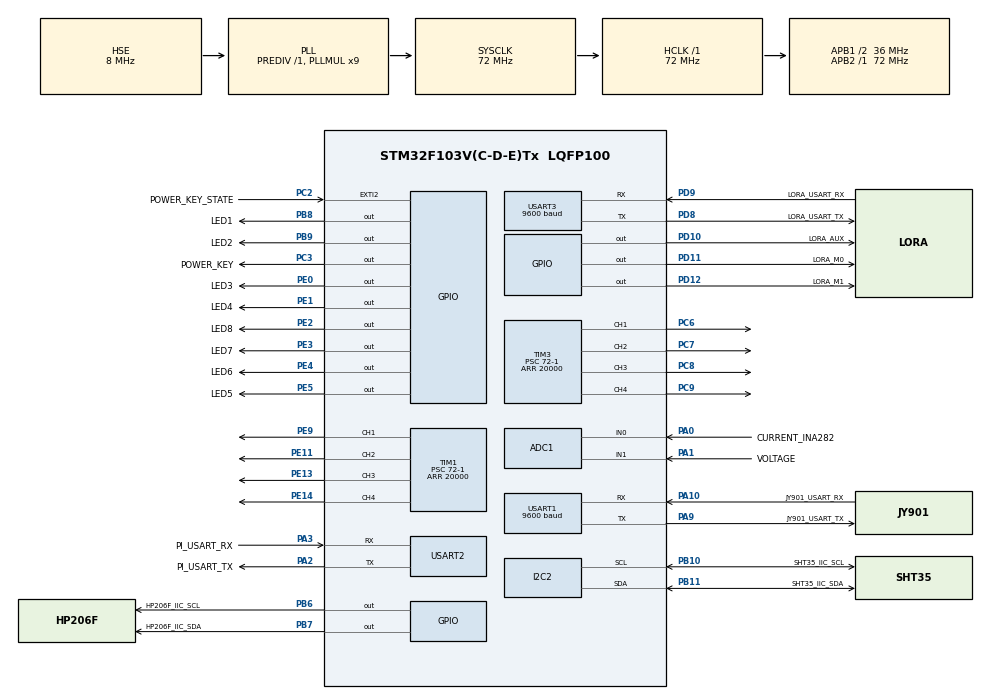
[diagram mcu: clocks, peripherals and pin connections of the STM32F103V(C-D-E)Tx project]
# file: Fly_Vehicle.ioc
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ADC1.Channel-0\#ChannelRegularConversion=ADC_CHANNEL_0
ADC1.Channel-3\#ChannelRegularConversion=ADC_CHANNEL_1
ADC1.ContinuousConvMode=ENABLE
ADC1.InjNumberOfConversion=0
ADC1.NbrOfConversion=2
ADC1.NbrOfConversionFlag=1
ADC1.Rank-0\#ChannelRegularConversion=1
ADC1.Rank-3\#ChannelRegularConversion=2
ADC1.SamplingTime-0\#ChannelRegularConversion=ADC_SAMPLETIME_239CYCLES_5
ADC1.SamplingTime-3\#ChannelRegularConversion=ADC_SAMPLETIME_239CYCLES_5
ADC1.master=1
Dma.ADC1.2.Direction=DMA_PERIPH_TO_MEMORY
Dma.ADC1.2.Instance=DMA1_Channel1
Dma.ADC1.2.MemDataAlignment=DMA_MDATAALIGN_WORD
Dma.ADC1.2.MemInc=DMA_MINC_ENABLE
Dma.ADC1.2.Mode=DMA_CIRCULAR
Dma.ADC1.2.PeriphDataAlignment=DMA_PDATAALIGN_WORD
Dma.ADC1.2.PeriphInc=DMA_PINC_DISABLE
Dma.ADC1.2.Priority=DMA_PRIORITY_LOW
Dma.Request0=USART1_RX
Dma.Request1=USART3_RX
Dma.Request2=ADC1
Dma.Request3=USART2_RX
Dma.Request4=USART2_TX
Dma.USART1_RX.0.Direction=DMA_PERIPH_TO_MEMORY
Dma.USART1_RX.0.Instance=DMA1_Channel5
Dma.USART1_RX.0.MemDataAlignment=DMA_MDATAALIGN_BYTE
Dma.USART1_RX.0.MemInc=DMA_MINC_ENABLE
Dma.USART1_RX.0.Mode=DMA_CIRCULAR
Dma.USART1_RX.0.PeriphDataAlignment=DMA_PDATAALIGN_BYTE
Dma.USART1_RX.0.PeriphInc=DMA_PINC_DISABLE
Dma.USART1_RX.0.Priority=DMA_PRIORITY_LOW
Dma.USART2_RX.3.Direction=DMA_PERIPH_TO_MEMORY
Dma.USART2_RX.3.Instance=DMA1_Channel6
Dma.USART2_RX.3.MemDataAlignment=DMA_MDATAALIGN_BYTE
Dma.USART2_RX.3.MemInc=DMA_MINC_ENABLE
Dma.USART2_RX.3.Mode=DMA_CIRCULAR
Dma.USART2_RX.3.PeriphDataAlignment=DMA_PDATAALIGN_BYTE
Dma.USART2_RX.3.PeriphInc=DMA_PINC_DISABLE
Dma.USART2_RX.3.Priority=DMA_PRIORITY_LOW
Dma.USART2_TX.4.Direction=DMA_MEMORY_TO_PERIPH
Dma.USART2_TX.4.Instance=DMA1_Channel7
Dma.USART2_TX.4.MemDataAlignment=DMA_MDATAALIGN_BYTE
Dma.USART2_TX.4.MemInc=DMA_MINC_ENABLE
Dma.USART2_TX.4.Mode=DMA_NORMAL
Dma.USART2_TX.4.PeriphDataAlignment=DMA_PDATAALIGN_BYTE
Dma.USART2_TX.4.PeriphInc=DMA_PINC_DISABLE
Dma.USART2_TX.4.Priority=DMA_PRIORITY_LOW
Dma.USART3_RX.1.Direction=DMA_PERIPH_TO_MEMORY
Dma.USART3_RX.1.Instance=DMA1_Channel3
Dma.USART3_RX.1.MemDataAlignment=DMA_MDATAALIGN_BYTE
Dma.USART3_RX.1.MemInc=DMA_MINC_ENABLE
Dma.USART3_RX.1.Mode=DMA_CIRCULAR
Dma.USART3_RX.1.PeriphDataAlignment=DMA_PDATAALIGN_BYTE
Dma.USART3_RX.1.PeriphInc=DMA_PINC_DISABLE
Dma.USART3_RX.1.Priority=DMA_PRIORITY_LOW
FREERTOS.INCLUDE_vTaskDelayUntil=1
FREERTOS.Tasks01=messageTask,0,500,message_Task_Function,As weak,NULL,Dynamic,NULL,NULL;sensorTask,-3,128,sensor_Task_Function,As weak,NULL,Dynamic,NULL,NULL;controlTask,-3,128,control_Task_Function,As weak,NULL,Dynamic,NULL,NULL;imuTask,-3,128,imu_Task_Function,As weak,NULL,Dynamic,NULL,NULL;ledTask,-3,128,led_Task_Function,As weak,NULL,Dynamic,NULL,NULL;pressureTask,2,128,pressure_Task_Function,As weak,NULL,Dynamic,NULL,NULL
FREERTOS.configTOTAL_HEAP_SIZE=8192
Mcu.Family=STM32F1
Mcu.Name=STM32F103V(C-D-E)Tx
Mcu.Package=LQFP100
NVIC.DMA1_Channel1_IRQn=true\:5\:0\:false\:false\:true\:true\:false\:true
NVIC.DMA1_Channel3_IRQn=true\:5\:0\:false\:false\:true\:true\:false\:true
NVIC.DMA1_Channel5_IRQn=true\:5\:0\:false\:false\:true\:true\:false\:true
NVIC.DMA1_Channel6_IRQn=true\:5\:0\:false\:false\:true\:true\:false\:true
NVIC.DMA1_Channel7_IRQn=true\:5\:0\:false\:false\:true\:true\:false\:true
NVIC.EXTI2_IRQn=true\:5\:0\:false\:false\:true\:true\:true\:true
NVIC.PriorityGroup=NVIC_PRIORITYGROUP_4
NVIC.TIM7_IRQn=true\:0\:0\:false\:false\:true\:false\:false\:true
NVIC.TimeBase=TIM7_IRQn
NVIC.TimeBaseIP=TIM7
NVIC.USART1_IRQn=true\:5\:0\:false\:false\:true\:true\:true\:true
NVIC.USART2_IRQn=true\:5\:0\:false\:false\:true\:true\:true\:true
NVIC.USART3_IRQn=true\:5\:0\:false\:false\:true\:true\:true\:true
OSC_IN.Mode=HSE-External-Oscillator
OSC_IN.Signal=RCC_OSC_IN
OSC_OUT.Mode=HSE-External-Oscillator
OSC_OUT.Signal=RCC_OSC_OUT
PA0-WKUP.GPIO_Label=CURRENT_INA282
PA0-WKUP.Signal=ADCx_IN0
PA1.GPIO_Label=VOLTAGE
PA1.Signal=ADCx_IN1
PA10.GPIO_Label=JY901_USART_RX
PA10.Mode=Asynchronous
PA10.Signal=USART1_RX
PA13.Mode=Serial_Wire
PA13.Signal=SYS_JTMS-SWDIO
PA14.Mode=Serial_Wire
PA14.Signal=SYS_JTCK-SWCLK
PA2.GPIO_Label=PI_USART_TX
PA2.Mode=Asynchronous
PA2.Signal=USART2_TX
PA3.GPIO_Label=PI_USART_RX
PA3.Mode=Asynchronous
PA3.Signal=USART2_RX
PA9.GPIO_Label=JY901_USART_TX
PA9.Mode=Asynchronous
PA9.Signal=USART1_TX
PB10.GPIO_Label=SHT35_IIC_SCL
PB10.Mode=I2C
PB10.Signal=I2C2_SCL
PB11.GPIO_Label=SHT35_IIC_SDA
PB11.Mode=I2C
PB11.Signal=I2C2_SDA
PB6.GPIO_Label=HP206F_IIC_SCL
PB6.GPIO_Speed=GPIO_SPEED_FREQ_HIGH
PB6.PinState=GPIO_PIN_SET
PB6.Signal=GPIO_Output
PB7.GPIO_Label=HP206F_IIC_SDA
PB7.GPIO_Speed=GPIO_SPEED_FREQ_HIGH
PB7.PinState=GPIO_PIN_SET
PB7.Signal=GPIO_Output
PB8.GPIO_Label=LED1
PB8.Signal=GPIO_Output
PB9.GPIO_Label=LED2
PB9.Signal=GPIO_Output
PC2.GPIO_Label=POWER_KEY_STATE
PC2.GPIO_ModeDefaultEXTI=GPIO_MODE_IT_FALLING
PC2.Signal=GPXTI2
PC3.GPIO_Label=POWER_KEY
PC3.PinState=GPIO_PIN_RESET
PC3.Signal=GPIO_Output
PC6.Signal=S_TIM3_CH1
PC7.Signal=S_TIM3_CH2
PC8.Signal=S_TIM3_CH3
PC9.Signal=S_TIM3_CH4
PD10.GPIO_Label=LORA_AUX
PD10.Signal=GPIO_Output
PD11.GPIO_Label=LORA_M0
PD11.Signal=GPIO_Output
PD12.GPIO_Label=LORA_M1
PD12.Signal=GPIO_Output
PD8.GPIO_Label=LORA_USART_TX
PD8.Mode=Asynchronous
PD8.Signal=USART3_TX
PD9.GPIO_Label=LORA_USART_RX
PD9.Mode=Asynchronous
PD9.Signal=USART3_RX
PE0.GPIO_Label=LED3
PE0.Signal=GPIO_Output
PE1.GPIO_Label=LED4
PE1.Signal=GPIO_Output
PE11.Signal=S_TIM1_CH2
PE13.Signal=S_TIM1_CH3
PE14.Signal=S_TIM1_CH4
PE2.GPIO_Label=LED8
PE2.Signal=GPIO_Output
PE3.GPIO_Label=LED7
PE3.Signal=GPIO_Output
PE4.GPIO_Label=LED6
PE4.Signal=GPIO_Output
PE5.GPIO_Label=LED5
PE5.Signal=GPIO_Output
PE9.Signal=S_TIM1_CH1
ProjectManager.HeapSize=0x200
ProjectManager.StackSize=0x400
ProjectManager.TargetToolchain=MDK-ARM V5
RCC.ADCPresc=RCC_ADCPCLK2_DIV6
RCC.AHBFreq_Value=72000000
RCC.APB1CLKDivider=RCC_HCLK_DIV2
RCC.APB1Freq_Value=36000000
RCC.APB1TimFreq_Value=72000000
RCC.APB2Freq_Value=72000000
RCC.APB2TimFreq_Value=72000000
RCC.HCLKFreq_Value=72000000
RCC.PLLMUL=RCC_PLL_MUL9
RCC.PLLSourceVirtual=RCC_PLLSOURCE_HSE
RCC.SYSCLKFreq_VALUE=72000000
RCC.SYSCLKSource=RCC_SYSCLKSOURCE_PLLCLK
RCC.USBFreq_Value=72000000
SH.ADCx_IN0.0=ADC1_IN0,IN0
SH.ADCx_IN1.0=ADC1_IN1,IN1
SH.S_TIM1_CH1.0=TIM1_CH1,PWM Generation1 CH1
SH.S_TIM1_CH2.0=TIM1_CH2,PWM Generation2 CH2
SH.S_TIM1_CH3.0=TIM1_CH3,PWM Generation3 CH3
SH.S_TIM1_CH4.0=TIM1_CH4,PWM Generation4 CH4
SH.S_TIM3_CH1.0=TIM3_CH1,PWM Generation1 CH1
SH.S_TIM3_CH2.0=TIM3_CH2,PWM Generation2 CH2
SH.S_TIM3_CH3.0=TIM3_CH3,PWM Generation3 CH3
SH.S_TIM3_CH4.0=TIM3_CH4,PWM Generation4 CH4
TIM1.Channel-PWM\ Generation1\ CH1=TIM_CHANNEL_1
TIM1.Channel-PWM\ Generation2\ CH2=TIM_CHANNEL_2
TIM1.Channel-PWM\ Generation3\ CH3=TIM_CHANNEL_3
TIM1.Channel-PWM\ Generation4\ CH4=TIM_CHANNEL_4
TIM1.Period=20000
TIM1.Prescaler=72-1
TIM1.Pulse-PWM\ Generation1\ CH1=1500
TIM1.Pulse-PWM\ Generation2\ CH2=1500
TIM1.Pulse-PWM\ Generation3\ CH3=1500
TIM1.Pulse-PWM\ Generation4\ CH4=1500
TIM3.Channel-PWM\ Generation1\ CH1=TIM_CHANNEL_1
TIM3.Channel-PWM\ Generation2\ CH2=TIM_CHANNEL_2
TIM3.Channel-PWM\ Generation3\ CH3=TIM_CHANNEL_3
TIM3.Channel-PWM\ Generation4\ CH4=TIM_CHANNEL_4
TIM3.Period=20000
TIM3.Prescaler=72-1
TIM3.Pulse-PWM\ Generation1\ CH1=1500
TIM3.Pulse-PWM\ Generation2\ CH2=1500
TIM3.Pulse-PWM\ Generation3\ CH3=1500
TIM3.Pulse-PWM\ Generation4\ CH4=1500
TIM6.Period=1
TIM6.Prescaler=72-1
USART1.BaudRate=9600
USART1.VirtualMode=VM_ASYNC
USART2.VirtualMode=VM_ASYNC
USART3.BaudRate=9600
USART3.VirtualMode=VM_ASYNC
VP_FREERTOS_VS_CMSIS_V1.Mode=CMSIS_V1
VP_SYS_VS_tim7.Mode=TIM7
VP_TIM6_VS_ClockSourceINT.Mode=Enable_Timer
board=custom

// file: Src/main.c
/* USER CODE BEGIN Header */
/**
  ******************************************************************************
  * @file           : main.c
  * @brief          : Main program body
  ******************************************************************************
  * @attention
  *
  * <h2><center>&copy; Copyright (c) 2019 STMicroelectronics.
  * All rights reserved.</center></h2>
  *
  * This software component is licensed by ST under Ultimate Liberty license
  * SLA0044, the "License"; You may not use this file except in compliance with
  * the License. You may obtain a copy of the License at:
  *                             www.st.com/SLA0044
  *
  ******************************************************************************
  */
/* USER CODE END Header */

#include "main.h"
#include "cmsis_os.h"
#include "adc.h"
#include "dma.h"
#include "i2c.h"
#include "tim.h"
#include "usart.h"
#include "gpio.h"

/* USER CODE BEGIN Includes */
#include "includes.h"
/* USER CODE END Includes */

void SystemClock_Config(void);
void MX_FREERTOS_Init(void);

extern uint16_t pwm_left;
extern uint16_t pwm_right;
extern uint16_t pwm_front;
extern uint16_t pwm_back;

extern uint16_t test_pwm;//所有默认值都是1500
extern uint16_t *test_pwm1;
extern uint16_t test_pwm2;
extern uint16_t *test_pwm3;
extern uint16_t test_pwm4;
extern uint16_t *test_pwm5;
extern uint16_t test_pwm6;
extern uint16_t *test_pwm7;
extern uint16_t test_pwm8;

extern uint8_t enter[];

uint8_t lora_ch;
bool osStart = 0;

extern void Control_0(void);
extern void Control_t(void);
extern void LED_SW(u8 num,u8 sta);

extern PI_UsartRec_t stm32_pi_Rec;
extern ControlMsg_t control_data;
extern UART_HandleTypeDef huart3;
extern enum MODE_CHOOSE{MODE0=0,MODEt}mode;

extern bool stop_startflag;

//void HAL_UART_TxCpltCallback(UART_HandleTypeDef *huart)
//{
//  /* Prevent unused argument(s) compilation warning */
//  HAL_UART3_Receive_IDLE(huart);
//  /* NOTE: This function Should not be modified, when the callback is needed,
//           the HAL_UART_TxCpltCallback could be implemented in the user file
//   */
//}这个没用

int main(void)
{

  /* MCU Configuration--------------------------------------------------------*/

  /* Reset of all peripherals, Initializes the Flash interface and the Systick. */
  HAL_Init();

  /* Configure the system clock */
  SystemClock_Config();

  /* Initialize all configured peripherals */
  MX_GPIO_Init();
  MX_DMA_Init();
  MX_ADC1_Init();
  MX_I2C2_Init();
  MX_TIM1_Init();
  MX_TIM3_Init();
  MX_USART1_UART_Init();
  MX_USART2_UART_Init();
  MX_USART3_UART_Init();
  MX_TIM6_Init();

//	MX_TIM5_Init();
  /* USER CODE BEGIN 2 */

  BSP_Init();

	LED_SW(1,1);
	stop_startflag=0;

//	while(1)//pwm测试
//	{
//		__HAL_TIM_SET_COMPARE(&htim1,TIM_CHANNEL_1,1450);//1   上下
//		__HAL_TIM_SET_COMPARE(&htim1,TIM_CHANNEL_2,1450);//
//		__HAL_TIM_SET_COMPARE(&htim1,TIM_CHANNEL_3,1450);//2   前后
//		__HAL_TIM_SET_COMPARE(&htim1,TIM_CHANNEL_4,1450);//
//
//		__HAL_TIM_SET_COMPARE(&htim3,TIM_CHANNEL_1,1450);//3   上下
//		__HAL_TIM_SET_COMPARE(&htim3,TIM_CHANNEL_2,1450);//
//		__HAL_TIM_SET_COMPARE(&htim3,TIM_CHANNEL_3,1450);//4   前后
//		__HAL_TIM_SET_COMPARE(&htim3,TIM_CHANNEL_4,1450);//

//		HAL_Delay(500);
//	}

//	__HAL_UART_ENABLE_IT(&SX1278_USART, UART_IT_RXNE);//

	delay_ms(3000);
  /* USER CODE END 2 */

	LED_SW(1,0);

//		pwm_right =1451;
//		pwm_left =1552;

////		__HAL_TIM_SET_COMPARE(&htim1,TIM_CHANNEL_1,test_pwm1);//1   上下，前
////		__HAL_TIM_SET_COMPARE(&htim1,TIM_CHANNEL_2,test_pwm2);//
////		__HAL_TIM_SET_COMPARE(&htim3,TIM_CHANNEL_1,test_pwm5);//3   上下，后
////		__HAL_TIM_SET_COMPARE(&htim3,TIM_CHANNEL_2,test_pwm6);//
//		__HAL_TIM_SET_COMPARE(&htim1,TIM_CHANNEL_3,*test_pwm3);//2   前后，右
//		__HAL_TIM_SET_COMPARE(&htim1,TIM_CHANNEL_4,*test_pwm3);//
//		__HAL_TIM_SET_COMPARE(&htim3,TIM_CHANNEL_3,*test_pwm7);//4   前后，左
//		__HAL_TIM_SET_COMPARE(&htim3,TIM_CHANNEL_4,*test_pwm7);//
//
//		HAL_UART_Transmit(&SX1278_USART, (uint8_t*)"in", 2, 0x100);
//		HAL_UART_Transmit(&SX1278_USART, enter, 2, 0x100);
//		__HAL_UART_ENABLE_IT(&PI_USART, UART_IT_IDLE);

	/* Call init function for freertos objects (in freertos.c) */
  MX_FREERTOS_Init();

	/* Start scheduler */
  osKernelStart();

  /* We should never get here as control is now taken by the scheduler */

  /* Infinite loop */
  /* USER CODE BEGIN WHILE */

//	HAL_UART_Transmit(&SX1278_USART, (uint8_t*)"55", 2, 0x100);//TC被置1但未能进入中断入口
//	if((__HAL_UART_GET_FLAG(&huart3,UART_FLAG_TC) != RESET))LED_SW(2,1);
//	delay_ms(2000);
//	HAL_UART_Transmit(&SX1278_USART, (uint8_t*)"55", 2, 0x100);//TC被置1但未能进入中断入口
//	if((__HAL_UART_GET_FLAG(&huart3,UART_FLAG_TC) != RESET))LED_SW(3,1);
//
	int count = 0;
	char string[20];
	uint8_t len_str;
//	control_data.navi_angle = 1;
//	control_data.navi_distance = 150;

  while (1)
  {
//		HAL_UART_Transmit(&SX1278_USART, (uint8_t*)"55", 2, 0x100);
//		delay_ms(500);

    /* USER CODE END WHILE */

//		if(stm32_pi_Rec.RX_flag)
//		{
////			HAL_UART_Transmit(&SX1278_USART, (uint8_t*)"55", 2, 0x100);
//			count++;
//			if(count==8){
//				//将control_data.navi_angle转为字符串，然后用串口分别发给树莓派和lora电脑端
//				len_str=sprintf(string,"dis=%3.3f\r\n",control_data.navi_distance);
//				HAL_UART_Transmit(&SX1278_USART, (uint8_t*)string, len_str, 0x100);
//				len_str=sprintf(string,"ang=%3.3f\r\n",control_data.navi_angle*180/3.14);
//				HAL_UART_Transmit(&SX1278_USART, (uint8_t*)string, len_str, 0x100);
//				count=0;
//			}

//			len_str=sprintf(string,"PWMinMAIN%d\r\n",test_pwm1);
//			HAL_UART_Transmit(&SX1278_USART, (uint8_t*)string, len_str, 0x100);

//		switch(mode){
//			case MODE0:{//工作模式0
//				Control_0();
//				delay_ms(300);
//				break;
//			}
//			case MODEt:{//工作模式t
//				Control_t();
//				break;
//			}
//			default:break;
//		}
//			stm32_pi_Rec.RX_flag=0;
//		}
//    /* USER CODE BEGIN 3 */
  }
  /* USER CODE END 3 */
}

void SystemClock_Config(void)
{
  RCC_OscInitTypeDef RCC_OscInitStruct = {0};
  RCC_ClkInitTypeDef RCC_ClkInitStruct = {0};
  RCC_PeriphCLKInitTypeDef PeriphClkInit = {0};

  /** Initializes the CPU, AHB and APB busses clocks
  */
  RCC_OscInitStruct.OscillatorType = RCC_OSCILLATORTYPE_HSE;
  RCC_OscInitStruct.HSEState = RCC_HSE_ON;
  RCC_OscInitStruct.HSEPredivValue = RCC_HSE_PREDIV_DIV1;
  RCC_OscInitStruct.HSIState = RCC_HSI_ON;
  RCC_OscInitStruct.PLL.PLLState = RCC_PLL_ON;
  RCC_OscInitStruct.PLL.PLLSource = RCC_PLLSOURCE_HSE;
  RCC_OscInitStruct.PLL.PLLMUL = RCC_PLL_MUL9;
  if (HAL_RCC_OscConfig(&RCC_OscInitStruct) != HAL_OK)
  {
    Error_Handler();
  }
  /** Initializes the CPU, AHB and APB busses clocks
  */
  RCC_ClkInitStruct.ClockType = RCC_CLOCKTYPE_HCLK|RCC_CLOCKTYPE_SYSCLK
                              |RCC_CLOCKTYPE_PCLK1|RCC_CLOCKTYPE_PCLK2;
  RCC_ClkInitStruct.SYSCLKSource = RCC_SYSCLKSOURCE_PLLCLK;
  RCC_ClkInitStruct.AHBCLKDivider = RCC_SYSCLK_DIV1;
  RCC_ClkInitStruct.APB1CLKDivider = RCC_HCLK_DIV2;
  RCC_ClkInitStruct.APB2CLKDivider = RCC_HCLK_DIV1;

  if (HAL_RCC_ClockConfig(&RCC_ClkInitStruct, FLASH_LATENCY_2) != HAL_OK)
  {
    Error_Handler();
  }
  PeriphClkInit.PeriphClockSelection = RCC_PERIPHCLK_ADC;
  PeriphClkInit.AdcClockSelection = RCC_ADCPCLK2_DIV6;
  if (HAL_RCCEx_PeriphCLKConfig(&PeriphClkInit) != HAL_OK)
  {
    Error_Handler();
  }
}

void HAL_TIM_PeriodElapsedCallback(TIM_HandleTypeDef *htim)
{
  if (htim->Instance == TIM7) {
    HAL_IncTick();
  }
  /* USER CODE BEGIN Callback 1 */
//	if (htim->Instance == TIM5) {
//		//code here
//
//
//
//	}
  /* USER CODE END Callback 1 */
}

void Error_Handler(void)
{
}

/************************ (C) COPYRIGHT STMicroelectronics *****END OF FILE****/

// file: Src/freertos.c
/* USER CODE BEGIN Header */
/**
  ******************************************************************************
  * File Name          : freertos.c
  * Description        : Code for freertos applications
  ******************************************************************************
  * @attention
  *
  * <h2><center>&copy; Copyright (c) 2019 STMicroelectronics.
  * All rights reserved.</center></h2>
  *
  * This software component is licensed by ST under Ultimate Liberty license
  * SLA0044, the "License"; You may not use this file except in compliance with
  * the License. You may obtain a copy of the License at:
  *                             www.st.com/SLA0044
  *
  ******************************************************************************
  */
/* USER CODE END Header */

#include "FreeRTOS.h"
#include "task.h"
#include "main.h"
#include "cmsis_os.h"

/* USER CODE BEGIN Includes */
#include "includes.h"
/* USER CODE END Includes */

osThreadId messageTaskHandle;
osThreadId sensorTaskHandle;
osThreadId controlTaskHandle;
osThreadId imuTaskHandle;
osThreadId ledTaskHandle;
osThreadId pressureTaskHandle;

void message_Task_Function(void const * argument);
void sensor_Task_Function(void const * argument);
void control_Task_Function(void const * argument);
void control_Ward_Function(void const * argument);
void imu_Task_Function(void const * argument);
void led_Task_Function(void const * argument);
void pressure_Task_Function(void const * argument);

void MX_FREERTOS_Init(void); /* (MISRA C 2004 rule 8.1) */

void MX_FREERTOS_Init(void) {

  /* USER CODE BEGIN RTOS_QUEUES */
  /* add queues, ... */
  Task_Queue_Semaphore_Timers_Create();
  /* USER CODE END RTOS_QUEUES */

  /* Create the thread(s) */
  /* definition and creation of messageTask */
  osThreadDef(messageTask, message_Task_Function, osPriorityNormal, 0, 500);
  messageTaskHandle = osThreadCreate(osThread(messageTask), NULL);

  /* definition and creation of sensorTask */
  osThreadDef(sensorTask, sensor_Task_Function, osPriorityIdle, 0, 128);
  sensorTaskHandle = osThreadCreate(osThread(sensorTask), NULL);

  /* definition and creation of controlTask */
  osThreadDef(controlTask, control_Task_Function, osPriorityIdle, 0, 128);
  controlTaskHandle = osThreadCreate(osThread(controlTask), NULL);

	 /* definition and creation of controlWardTask */
  osThreadDef(controlWardTask, control_Ward_Function, osPriorityIdle, 0, 128);
  controlTaskHandle = osThreadCreate(osThread(controlWardTask), NULL);

  /* definition and creation of imuTask */
  osThreadDef(imuTask, imu_Task_Function, osPriorityIdle, 0, 128);
  imuTaskHandle = osThreadCreate(osThread(imuTask), NULL);

  /* definition and creation of ledTask */
  osThreadDef(ledTask, led_Task_Function, osPriorityIdle, 0, 128);
  ledTaskHandle = osThreadCreate(osThread(ledTask), NULL);

  /* definition and creation of pressureTask */
  osThreadDef(pressureTask, pressure_Task_Function, osPriorityHigh, 0, 128);
  pressureTaskHandle = osThreadCreate(osThread(pressureTask), NULL);

}

__weak void message_Task_Function(void const * argument)
{

  for(;;)
  {
    osDelay(1);
  }
}

__weak void sensor_Task_Function(void const * argument)
{
  for(;;)
  {
    osDelay(1);
  }
}

__weak void control_Task_Function(void const * argument)
{
  /* USER CODE BEGIN control_Task_Function */
  /* Infinite loop */
  for(;;)
  {
		osDelay(1000);
  }
  /* USER CODE END control_Task_Function */
}

__weak void control_Ward_Function(void const * argument)
{
  /* USER CODE BEGIN control_Task_Function */
  /* Infinite loop */
  for(;;)
  {
		osDelay(1000);
  }
  /* USER CODE END control_Task_Function */
}

__weak void imu_Task_Function(void const * argument)
{
  /* USER CODE BEGIN imu_Task_Function */
  /* Infinite loop */
  for(;;)
  {
    osDelay(1000);
  }
  /* USER CODE END imu_Task_Function */
}

__weak void led_Task_Function(void const * argument)
{
  for(;;)
  {
    osDelay(1);
  }
}

__weak void pressure_Task_Function(void const * argument)
{
  for(;;)
  {
    osDelay(1);
  }
}

/************************ (C) COPYRIGHT STMicroelectronics *****END OF FILE****/
